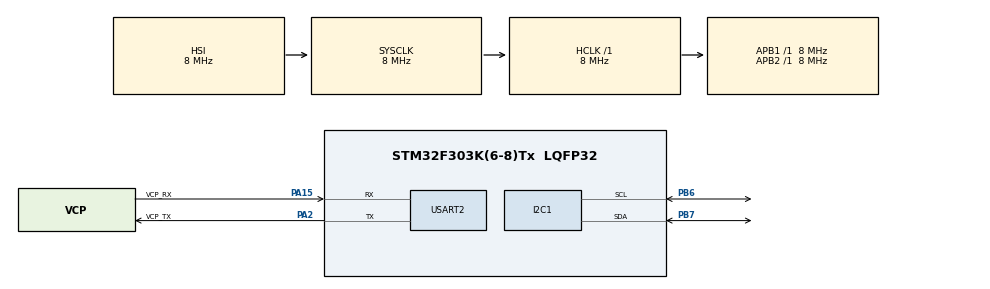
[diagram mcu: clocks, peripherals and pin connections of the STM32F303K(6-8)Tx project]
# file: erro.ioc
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Mcu.Family=STM32F3
Mcu.Name=STM32F303K(6-8)Tx
Mcu.Package=LQFP32
NVIC.PriorityGroup=NVIC_PRIORITYGROUP_4
PA13.GPIO_Label=SWDIO
PA13.Mode=Serial_Wire
PA13.Signal=SYS_JTMS-SWDIO
PA14.GPIO_Label=SWCLK
PA14.Mode=Serial_Wire
PA14.Signal=SYS_JTCK-SWCLK
PA15.GPIO_Label=VCP_RX
PA15.Mode=Asynchronous
PA15.Signal=USART2_RX
PA2.GPIO_Label=VCP_TX
PA2.Mode=Asynchronous
PA2.Signal=USART2_TX
PB6.Mode=I2C
PB6.Signal=I2C1_SCL
PB7.Mode=I2C
PB7.Signal=I2C1_SDA
PF0\ /\ OSC_IN.GPIO_Label=MCO
PF0\ /\ OSC_IN.Mode=HSE-External-Clock-Source
PF0\ /\ OSC_IN.Signal=RCC_OSC_IN
ProjectManager.HeapSize=0x200
ProjectManager.StackSize=0x400
ProjectManager.TargetToolchain=STM32CubeIDE
RCC.AHBFreq_Value=8000000
RCC.APB1Freq_Value=8000000
RCC.APB2Freq_Value=8000000
RCC.CortexFreq_Value=8000000
RCC.HSE_VALUE=8000000
RCC.HSI_VALUE=8000000
RCC.SYSCLKFreq_VALUE=8000000
USART2.VirtualMode-Asynchronous=VM_ASYNC
board=NUCLEO-F303K8

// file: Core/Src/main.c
/* USER CODE BEGIN Header */
/**
 ******************************************************************************
 * @file           : main.c
 * @brief          : Main program body
 ******************************************************************************
 * @attention
 *
 * Copyright (c) 2024 STMicroelectronics.
 * All rights reserved.
 *
 * This software is licensed under terms that can be found in the LICENSE file
 * in the root directory of this software component.
 * If no LICENSE file comes with this software, it is provided AS-IS.
 *
 ******************************************************************************
 */
/* USER CODE END Header */
#include "main.h"

I2C_HandleTypeDef hi2c1;

UART_HandleTypeDef huart2;

void SystemClock_Config(void);
static void MX_GPIO_Init(void);
static void MX_USART2_UART_Init(void);
static void MX_I2C1_Init(void);

int main(void) {

	/* MCU Configuration--------------------------------------------------------*/

	/* Reset of all peripherals, Initializes the Flash interface and the Systick. */
	HAL_Init();

	/* Configure the system clock */
	SystemClock_Config();

	/* Initialize all configured peripherals */
	MX_GPIO_Init();
	MX_USART2_UART_Init();
	MX_I2C1_Init();
	/* USER CODE BEGIN 2 */
	uint8_t buff;
	int intbuff;
	char str;
	/* USER CODE END 2 */

	/* Infinite loop */
	while (1) {
		intbuff = 1;
		sprintf(str, "%d\n\r", intbuff);
		HAL_UART_Transmit(&huart2, &str, strlen(str), 1000);
	}
}

void SystemClock_Config(void) {
	RCC_OscInitTypeDef RCC_OscInitStruct = { 0 };
	RCC_ClkInitTypeDef RCC_ClkInitStruct = { 0 };
	RCC_PeriphCLKInitTypeDef PeriphClkInit = { 0 };

	/** Initializes the RCC Oscillators according to the specified parameters
	 * in the RCC_OscInitTypeDef structure.
	 */
	RCC_OscInitStruct.OscillatorType = RCC_OSCILLATORTYPE_HSI;
	RCC_OscInitStruct.HSIState = RCC_HSI_ON;
	RCC_OscInitStruct.HSICalibrationValue = RCC_HSICALIBRATION_DEFAULT;
	RCC_OscInitStruct.PLL.PLLState = RCC_PLL_NONE;
	if (HAL_RCC_OscConfig(&RCC_OscInitStruct) != HAL_OK) {
		Error_Handler();
	}

	/** Initializes the CPU, AHB and APB buses clocks
	 */
	RCC_ClkInitStruct.ClockType = RCC_CLOCKTYPE_HCLK | RCC_CLOCKTYPE_SYSCLK
			| RCC_CLOCKTYPE_PCLK1 | RCC_CLOCKTYPE_PCLK2;
	RCC_ClkInitStruct.SYSCLKSource = RCC_SYSCLKSOURCE_HSI;
	RCC_ClkInitStruct.AHBCLKDivider = RCC_SYSCLK_DIV1;
	RCC_ClkInitStruct.APB1CLKDivider = RCC_HCLK_DIV1;
	RCC_ClkInitStruct.APB2CLKDivider = RCC_HCLK_DIV1;

	if (HAL_RCC_ClockConfig(&RCC_ClkInitStruct, FLASH_LATENCY_0) != HAL_OK) {
		Error_Handler();
	}
	PeriphClkInit.PeriphClockSelection = RCC_PERIPHCLK_I2C1;
	PeriphClkInit.I2c1ClockSelection = RCC_I2C1CLKSOURCE_HSI;
	if (HAL_RCCEx_PeriphCLKConfig(&PeriphClkInit) != HAL_OK) {
		Error_Handler();
	}
}

static void MX_I2C1_Init(void) {

	hi2c1.Instance = I2C1;
	hi2c1.Init.Timing = 0x2000090E;
	hi2c1.Init.OwnAddress1 = 0;
	hi2c1.Init.AddressingMode = I2C_ADDRESSINGMODE_7BIT;
	hi2c1.Init.DualAddressMode = I2C_DUALADDRESS_DISABLE;
	hi2c1.Init.OwnAddress2 = 0;
	hi2c1.Init.OwnAddress2Masks = I2C_OA2_NOMASK;
	hi2c1.Init.GeneralCallMode = I2C_GENERALCALL_DISABLE;
	hi2c1.Init.NoStretchMode = I2C_NOSTRETCH_DISABLE;
	if (HAL_I2C_Init(&hi2c1) != HAL_OK) {
		Error_Handler();
	}

	/** Configure Analogue filter
	 */
	if (HAL_I2CEx_ConfigAnalogFilter(&hi2c1, I2C_ANALOGFILTER_ENABLE)
			!= HAL_OK) {
		Error_Handler();
	}

	/** Configure Digital filter
	 */
	if (HAL_I2CEx_ConfigDigitalFilter(&hi2c1, 0) != HAL_OK) {
		Error_Handler();
	}

}

static void MX_USART2_UART_Init(void) {

	huart2.Instance = USART2;
	huart2.Init.BaudRate = 38400;
	huart2.Init.WordLength = UART_WORDLENGTH_8B;
	huart2.Init.StopBits = UART_STOPBITS_1;
	huart2.Init.Parity = UART_PARITY_NONE;
	huart2.Init.Mode = UART_MODE_TX_RX;
	huart2.Init.HwFlowCtl = UART_HWCONTROL_NONE;
	huart2.Init.OverSampling = UART_OVERSAMPLING_16;
	huart2.Init.OneBitSampling = UART_ONE_BIT_SAMPLE_DISABLE;
	huart2.AdvancedInit.AdvFeatureInit = UART_ADVFEATURE_NO_INIT;
	if (HAL_UART_Init(&huart2) != HAL_OK) {
		Error_Handler();
	}

}

static void MX_GPIO_Init(void) {

	/* GPIO Ports Clock Enable */
	__HAL_RCC_GPIOF_CLK_ENABLE();
	__HAL_RCC_GPIOA_CLK_ENABLE();
	__HAL_RCC_GPIOB_CLK_ENABLE();

}

void Error_Handler(void) {
	__disable_irq();
	while (1) {
	}
}
